AUTOSAR XML (schema 4-0-3)
standard types defined: Boolean
package /AUTOSAR_Platform/DataConstrs
  range DC_Boolean: raw 0..1
package /PATAC/Facility/DataTypes/Implementation
  compu method COMPU_Boolean: 0=FALSE, 1=TRUE
  unit NoUnit: factor-si-to-unit=1, offset-si-to-unit=0
package /PATAC/MSM/ModeAdjust
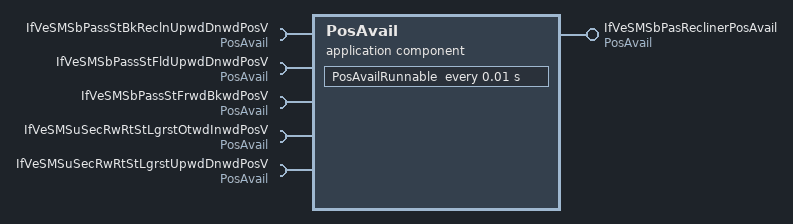
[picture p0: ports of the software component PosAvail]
  application sw component type PosAvail
    provide port IfVeSMSbPasReclinerPosAvail: nonqueued-sender-com-spec{data-element=Val, init-value=0}, provided-interface=PosAvail
    5 x require port, all with nonqueued-receiver-com-spec{data-element=Val, filter=data-filter-type=ALWAYS, init-value=0}, required-interface=PosAvail:
      IfVeSMSbPassStBkReclnUpwdDnwdPosV
      IfVeSMSbPassStFldUpwdDnwdPosV
      IfVeSMSbPassStFrwdBkwdPosV
      IfVeSMSuSecRwRtStLgrstOtwdInwdPosV
      IfVeSMSuSecRwRtStLgrstUpwdDnwdPosV
    behavior PosAvail_InternalBehavior
      timing event TMT_PosAvailRunnable: start-on-event=PosAvailRunnable, period=0.01
      runnable PosAvailRunnable
        data-receive-point-by-arguments:
          5 x access:
            REC_IfVeSMSbPassStBkReclnUpwdDnwdPosV_Val: accessed-variable=IfVeSMSbPassStBkReclnUpwdDnwdPosV.Val
            REC_IfVeSMSbPassStFldUpwdDnwdPosV_Val: accessed-variable=IfVeSMSbPassStFldUpwdDnwdPosV.Val
            REC_IfVeSMSbPassStFrwdBkwdPosV_Val: accessed-variable=IfVeSMSbPassStFrwdBkwdPosV.Val
            REC_IfVeSMSuSecRwRtStLgrstOtwdInwdPosV_Val: accessed-variable=IfVeSMSuSecRwRtStLgrstOtwdInwdPosV.Val
            REC_IfVeSMSuSecRwRtStLgrstUpwdDnwdPosV_Val: accessed-variable=IfVeSMSuSecRwRtStLgrstUpwdDnwdPosV.Val
        data-send-points:
          access SEND_IfVeSMSbPasReclinerPosAvail_Val: accessed-variable=IfVeSMSbPasReclinerPosAvail.Val
  swc implementation PosAvail_Implementation: behavior=PosAvail_InternalBehavior
    code-descriptors:
      code Default: artifact-descriptors=autosar-engineering-object={short-label=Default, category=SWSRC}
package /PATAC/MSM/ModeAdjust/PortInterface
  sender receiver interface PosAvail: invalidation-policy{data-element=Val, handle-invalid=DONT-INVALIDATE}
    data Val: type=Boolean
